# csr register map
Registers from a debugger description file.
Registers are 8-bit, access not given, no defined reset value unless marked. A register's access mark holds for its fields unless they carry their own. Addresses are absolute; registers are grouped by the start of their names; lines under a group give offsets from that group; [hi:lo] are bit positions; {n}, {i} and the like mark numbered series; 'fields as' and 'values as' point back to an identical list; <NAME> marks a mode.

## SFR_CSRMemory
0x00 ustatus
0x04 uie
0x05 utvec
0x40 uscratch
0x41 uepc
0x42 ucause
0x43 utval
0x44 uip
0x100 sstatus
0x102 sedeleg
0x103 sideleg
0x104 sie
0x105 stvec
0x106 scounteren
0x140 sscratch
0x141 sepc
0x142 scause
0x143 stval
0x144 sip
0x180 satp
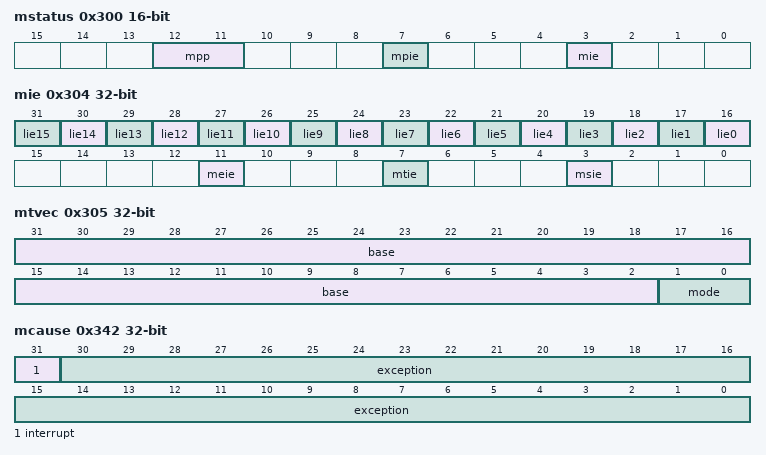
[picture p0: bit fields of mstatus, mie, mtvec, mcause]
0x300 mstatus 16-bit
  [12:11] mpp, [7] mpie, [3] mie
0x301 misa
0x302 medeleg
0x303 mideleg
0x304 mie 32-bit
  [n+16] lie{n} (n=0..15), [11] meie, [7] mtie, [3] msie
0x305 mtvec 32-bit
  [31:2] base, [1:0] mode
0x307 mtvt
{0x320+i} mhpmevent{i} (i=3..31)
0x340 mscratch
0x341 mepc
0x342 mcause 32-bit
  [31] interrupt, [30:0] exception
0x343 mtval
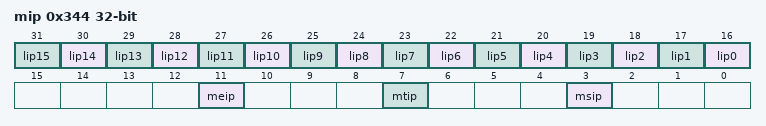
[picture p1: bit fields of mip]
0x344 mip 32-bit ro
  [n+16] lip{n} (n=0..15), [11] meip, [7] mtip, [3] msip
0x345 mnxti
0x346 mintstatus
0x348 mscratchcsw
0x349 mscratchcswl
{0x3A0+i} pmpcfg{i} (i=0..3)
{0x3B0+i} pmpaddr{i} (i=0..15)
0x7A0 tselect
{0x7A0+i} tdata{i} (i=1..3)
0x7B0 dcsr
0x7B1 dpc
0x7B2 dscratch
0xB00 mcycle
0xB02 minstret
{0xB00+i} mhpmcounter{i} (i=3..31)
0xB80 mcycleh
0xB82 minstreth
{0xB80+i} mhpmcounter{i}h (i=3..31)
0xC00 cycle ro
0xC01 time ro
0xC02 instret ro
{0xC00+i} hpmcounter{i} ro (i=3..30)
0xC1F hpmcounter31
0xC80 cycleh ro
0xC81 timeh ro
0xC82 instreth ro
{0xC80+i} hpmcounter{i}h ro (i=3..31)
0xF11 mvendorid ro
0xF12 marchid ro
0xF13 mimpid ro
0xF14 mhartid ro

## Notices in the file
Copyright 2019 IAR Systems AB.
